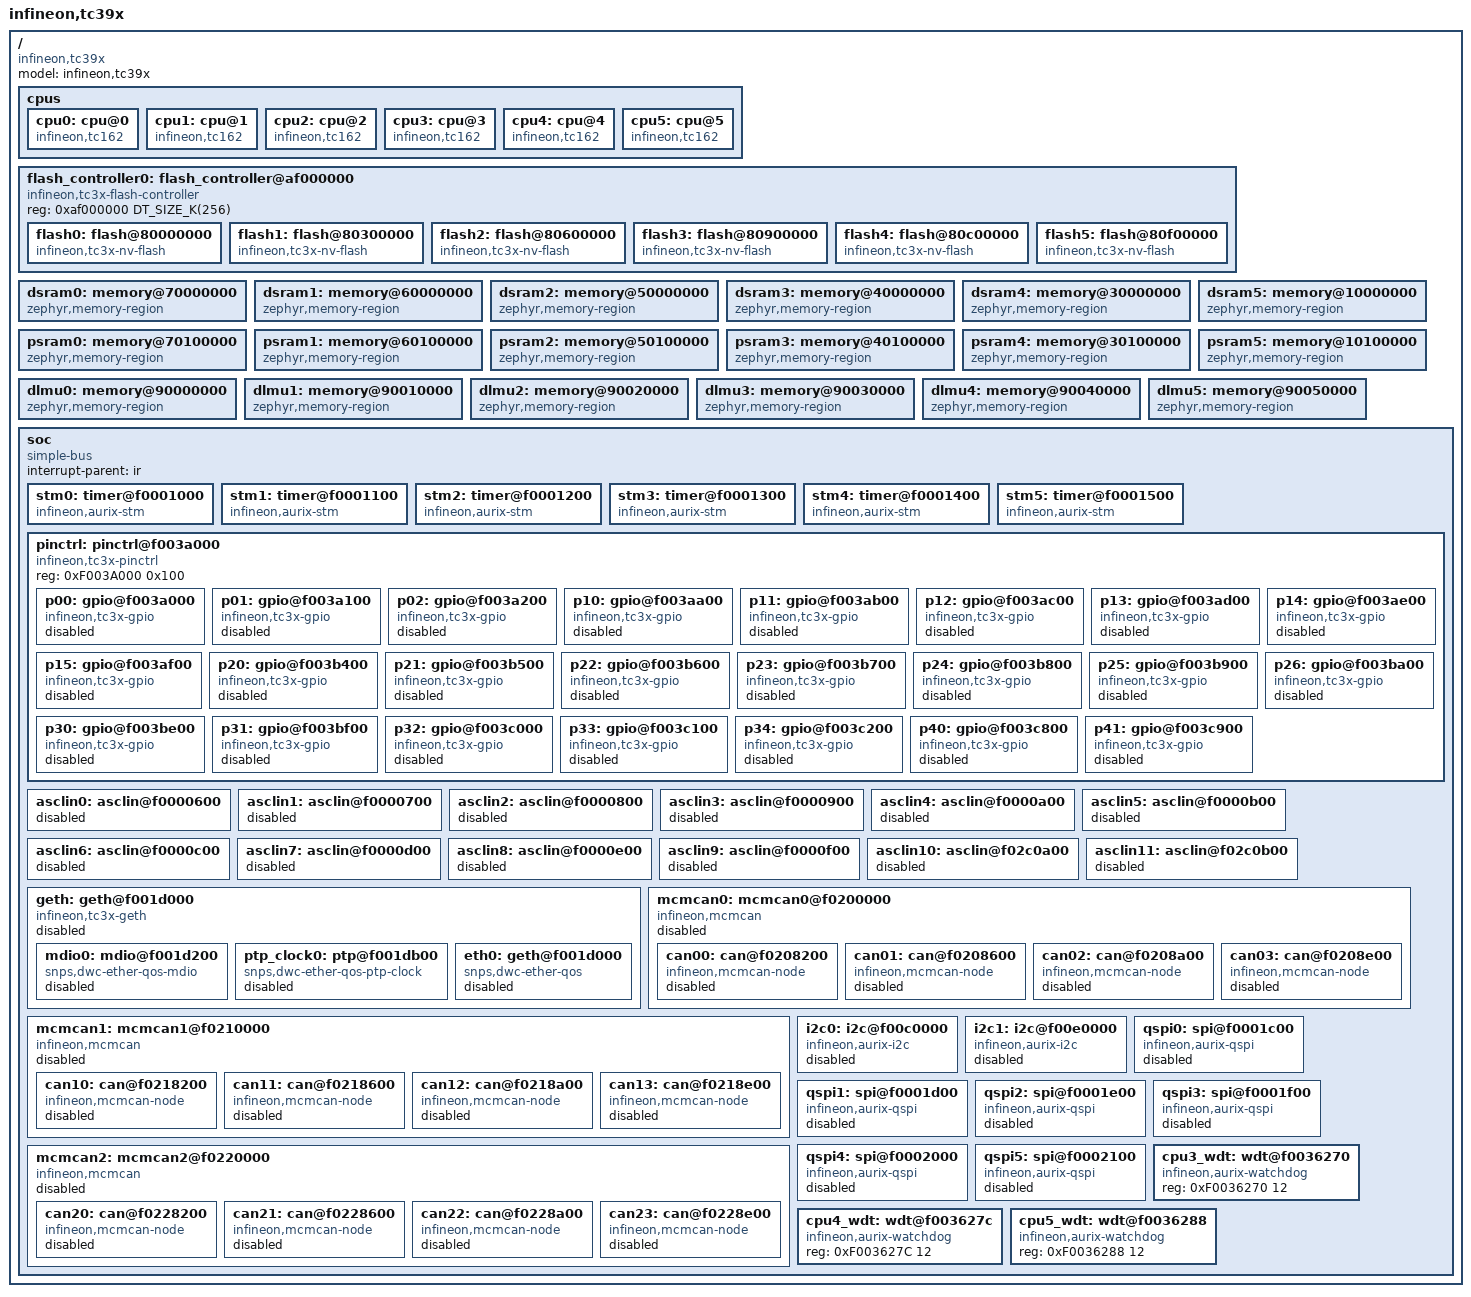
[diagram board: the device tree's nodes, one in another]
/*
 * Copyright (c) 2024 Infineon Technologies AG
 *
 * SPDX-License-Identifier: Apache-2.0
 */

#include <mem.h>
#include <freq.h>
#include <skeleton.dtsi>
#include <zephyr/dt-bindings/clock/tc3x_clock.h>
#include <zephyr/dt-bindings/gpio/gpio.h>
#include <infineon/tc3x/tc39x-irq.h>
#include <infineon/tc3x/tc3x-common.dtsi>

/ {
	model = "infineon,tc39x";
	compatible = "infineon,tc39x";

	cpus {
		#address-cells = <1>;
		#size-cells = <0>;

		cpu0: cpu@0 {
			compatible = "infineon,tc162";
			reg = <0>;
			clocks = <&fcpu0>;
		};
		cpu1: cpu@1 {
			compatible = "infineon,tc162";
			reg = <1>;
			clocks = <&fcpu1>;
		};
		cpu2: cpu@2 {
			compatible = "infineon,tc162";
			reg = <2>;
			clocks = <&fcpu2>;
		};
		cpu3: cpu@3 {
			compatible = "infineon,tc162";
			reg = <3>;
			clocks = <&fcpu3>;
		};
		cpu4: cpu@4 {
			compatible = "infineon,tc162";
			reg = <4>;
			clocks = <&fcpu4>;
		};
		cpu5: cpu@5 {
			compatible = "infineon,tc162";
			reg = <5>;
			clocks = <&fcpu5>;
		};
	};

	flash_controller0: flash_controller@af000000 {
		compatible = "infineon,tc3x-flash-controller";
		#address-cells = <1>;
		#size-cells = <1>;
		reg = <0xaf000000 DT_SIZE_K(256)>;
		flash0: flash@80000000 {
			compatible = "infineon,tc3x-nv-flash","soc-nv-flash";
			write-block-size = <256>;
			reg = <0x80000000 DT_SIZE_M(3)>;
		};
		flash1: flash@80300000 {
			compatible = "infineon,tc3x-nv-flash","soc-nv-flash";
			write-block-size = <256>;
			reg = <0x80300000 DT_SIZE_M(3)>;
		};
		flash2: flash@80600000 {
			compatible = "infineon,tc3x-nv-flash","soc-nv-flash";
			write-block-size = <256>;
			reg = <0x80600000 DT_SIZE_M(3)>;
		};
		flash3: flash@80900000 {
			compatible = "infineon,tc3x-nv-flash","soc-nv-flash";
			write-block-size = <256>;
			reg = <0x80900000 DT_SIZE_M(3)>;
		};
		flash4: flash@80c00000 {
			compatible = "infineon,tc3x-nv-flash","soc-nv-flash";
			write-block-size = <256>;
			reg = <0x80c00000 DT_SIZE_M(3)>;
		};
		flash5: flash@80f00000 {
			compatible = "infineon,tc3x-nv-flash","soc-nv-flash";
			write-block-size = <256>;
			reg = <0x80f00000 DT_SIZE_M(1)>;
		};
	};

	dsram0: memory@70000000 {
		compatible = "zephyr,memory-region","mmio-sram";
		reg = <0x70000000 DT_SIZE_K(240)>;
		zephyr,memory-region = "DSRAM0";
	};
	dsram1: memory@60000000 {
		compatible = "zephyr,memory-region","mmio-sram";
		reg = <0x60000000 DT_SIZE_K(240)>;
		zephyr,memory-region = "DSRAM1";
	};
	dsram2: memory@50000000 {
		compatible = "zephyr,memory-region","mmio-sram";
		reg = <0x50000000 DT_SIZE_K(96)>;
		zephyr,memory-region = "DSRAM2";
	};
	dsram3: memory@40000000 {
		compatible = "zephyr,memory-region","mmio-sram";
		reg = <0x40000000 DT_SIZE_K(96)>;
		zephyr,memory-region = "DSRAM3";
	};
	dsram4: memory@30000000 {
		compatible = "zephyr,memory-region","mmio-sram";
		reg = <0x30000000 DT_SIZE_K(96)>;
		zephyr,memory-region = "DSRAM4";
	};
	dsram5: memory@10000000 {
		compatible = "zephyr,memory-region","mmio-sram";
		reg = <0x10000000 DT_SIZE_K(96)>;
		zephyr,memory-region = "DSRAM5";
	};

	psram0: memory@70100000 {
		compatible = "zephyr,memory-region","mmio-sram";
		reg = <0x70100000 DT_SIZE_K(64)>;
		zephyr,memory-region = "PSRAM0";
	};
	psram1: memory@60100000 {
		compatible = "zephyr,memory-region","mmio-sram";
		reg = <0x60100000 DT_SIZE_K(64)>;
		zephyr,memory-region = "PSRAM1";
	};
	psram2: memory@50100000 {
		compatible = "zephyr,memory-region","mmio-sram";
		reg = <0x50100000 DT_SIZE_K(64)>;
		zephyr,memory-region = "PSRAM2";
	};
	psram3: memory@40100000 {
		compatible = "zephyr,memory-region","mmio-sram";
		reg = <0x40100000 DT_SIZE_K(64)>;
		zephyr,memory-region = "PSRAM3";
	};
	psram4: memory@30100000 {
		compatible = "zephyr,memory-region","mmio-sram";
		reg = <0x30100000 DT_SIZE_K(64)>;
		zephyr,memory-region = "PSRAM4";
	};
	psram5: memory@10100000 {
		compatible = "zephyr,memory-region","mmio-sram";
		reg = <0x10100000 DT_SIZE_K(64)>;
		zephyr,memory-region = "PSRAM5";
	};

	dlmu0: memory@90000000 {
		compatible = "zephyr,memory-region","mmio-sram";
		reg = <0x90000000 DT_SIZE_K(64)>;
		zephyr,memory-region = "DLMU0";
	};

	dlmu1: memory@90010000 {
		compatible = "zephyr,memory-region","mmio-sram";
		reg = <0x90010000 DT_SIZE_K(64)>;
		zephyr,memory-region = "DLMU1";
	};

	dlmu2: memory@90020000 {
		compatible = "zephyr,memory-region","mmio-sram";
		reg = <0x90020000 DT_SIZE_K(64)>;
		zephyr,memory-region = "DLMU2";
	};

	dlmu3: memory@90030000 {
		compatible = "zephyr,memory-region","mmio-sram";
		reg = <0x90030000 DT_SIZE_K(64)>;
		zephyr,memory-region = "DLMU3";
	};

	dlmu4: memory@90040000 {
		compatible = "zephyr,memory-region","mmio-sram";
		reg = <0x90040000 DT_SIZE_K(64)>;
		zephyr,memory-region = "DLMU4";
	};

	dlmu5: memory@90050000 {
		compatible = "zephyr,memory-region","mmio-sram";
		reg = <0x90050000 DT_SIZE_K(64)>;
		zephyr,memory-region = "DLMU5";
	};

	soc {
		#address-cells = <1>;
		#size-cells = <1>;
		interrupt-parent = <&ir>;
		compatible = "simple-bus";
		ranges;

		stm0: timer@f0001000 {
			compatible = "infineon,aurix-stm";
			reg = <0xF0001000 256>;
			clocks = <&fstm>;
			interrupts = <IRQ_STM0_SR0 1>;
		};
		stm1: timer@f0001100 {
			compatible = "infineon,aurix-stm";
			reg = <0xF0001100 256>;
			clocks = <&fstm>;
			interrupts = <IRQ_STM1_SR0 1>;
		};
		stm2: timer@f0001200 {
			compatible = "infineon,aurix-stm";
			reg = <0xF0001200 256>;
			clocks = <&fstm>;
			interrupts = <IRQ_STM2_SR0 1>;
		};
		stm3: timer@f0001300 {
			compatible = "infineon,aurix-stm";
			reg = <0xF0001300 256>;
			clocks = <&fstm>;
			interrupts = <IRQ_STM3_SR0 1>;
		};
		stm4: timer@f0001400 {
			compatible = "infineon,aurix-stm";
			reg = <0xF0001400 256>;
			clocks = <&fstm>;
			interrupts = <IRQ_STM4_SR0 1>;
		};
		stm5: timer@f0001500 {
			compatible = "infineon,aurix-stm";
			reg = <0xF0001500 256>;
			clocks = <&fstm>;
			interrupts = <IRQ_STM5_SR0 1>;
		};

		pinctrl: pinctrl@f003a000 {
			compatible = "infineon,tc3x-pinctrl";
			reg = <0xF003A000 0x100>;
			#address-cells = <1>;
			#size-cells = <1>;

			p00: gpio@f003a000 {
				compatible = "infineon,tc3x-gpio";
				reg = <0xF003A000 0x100>;
				gpio-controller;
				#gpio-cells = <2>;
				status = "disabled";
			};
			p01: gpio@f003a100 {
				compatible = "infineon,tc3x-gpio";
				reg = <0xF003A100 0x100>;
				gpio-controller;
				#gpio-cells = <2>;
				status = "disabled";
			};
			p02: gpio@f003a200 {
				compatible = "infineon,tc3x-gpio";
				reg = <0xF003A200 0x100>;
				gpio-controller;
				#gpio-cells = <2>;
				status = "disabled";
			};
			p10: gpio@f003aa00 {
				compatible = "infineon,tc3x-gpio";
				reg = <0xF003AA00 0x100>;
				gpio-controller;
				#gpio-cells = <2>;
				status = "disabled";
			};
			p11: gpio@f003ab00 {
				compatible = "infineon,tc3x-gpio";
				reg = <0xF003AB00 0x100>;
				gpio-controller;
				#gpio-cells = <2>;
				status = "disabled";
			};
			p12: gpio@f003ac00 {
				compatible = "infineon,tc3x-gpio";
				reg = <0xF003AC00 0x100>;
				gpio-controller;
				#gpio-cells = <2>;
				status = "disabled";
			};
			p13: gpio@f003ad00 {
				compatible = "infineon,tc3x-gpio";
				reg = <0xF003AD00 0x100>;
				gpio-controller;
				#gpio-cells = <2>;
				status = "disabled";
			};
			p14: gpio@f003ae00 {
				compatible = "infineon,tc3x-gpio";
				reg = <0xF003AE00 0x100>;
				gpio-controller;
				#gpio-cells = <2>;
				status = "disabled";
			};
			p15: gpio@f003af00 {
				compatible = "infineon,tc3x-gpio";
				reg = <0xF003AF00 0x100>;
				gpio-controller;
				#gpio-cells = <2>;
				status = "disabled";
			};
			p20: gpio@f003b400 {
				compatible = "infineon,tc3x-gpio";
				reg = <0xF003B400 0x100>;
				gpio-controller;
				#gpio-cells = <2>;
				status = "disabled";
			};
			p21: gpio@f003b500 {
				compatible = "infineon,tc3x-gpio";
				reg = <0xF003B500 0x100>;
				gpio-controller;
				#gpio-cells = <2>;
				status = "disabled";
			};
			p22: gpio@f003b600 {
				compatible = "infineon,tc3x-gpio";
				reg = <0xF003B600 0x100>;
				gpio-controller;
				#gpio-cells = <2>;
				status = "disabled";
			};
			p23: gpio@f003b700 {
				compatible = "infineon,tc3x-gpio";
				reg = <0xF003B700 0x100>;
				gpio-controller;
				#gpio-cells = <2>;
				status = "disabled";
			};
			p24: gpio@f003b800 {
				compatible = "infineon,tc3x-gpio";
				reg = <0xF003B800 0x100>;
				gpio-controller;
				#gpio-cells = <2>;
				status = "disabled";
			};
			p25: gpio@f003b900 {
				compatible = "infineon,tc3x-gpio";
				reg = <0xF003B900 0x100>;
				gpio-controller;
				#gpio-cells = <2>;
				status = "disabled";
			};
			p26: gpio@f003ba00 {
				compatible = "infineon,tc3x-gpio";
				reg = <0xF003BA00 0x100>;
				gpio-controller;
				#gpio-cells = <2>;
				status = "disabled";
			};
			p30: gpio@f003be00 {
				compatible = "infineon,tc3x-gpio";
				reg = <0xF003BE00 0x100>;
				gpio-controller;
				#gpio-cells = <2>;
				status = "disabled";
			};
			p31: gpio@f003bf00 {
				compatible = "infineon,tc3x-gpio";
				reg = <0xF003BF00 0x100>;
				gpio-controller;
				#gpio-cells = <2>;
				status = "disabled";
			};
			p32: gpio@f003c000 {
				compatible = "infineon,tc3x-gpio";
				reg = <0xF003C000 0x100>;
				gpio-controller;
				#gpio-cells = <2>;
				status = "disabled";
			};
			p33: gpio@f003c100 {
				compatible = "infineon,tc3x-gpio";
				reg = <0xF003C100 0x100>;
				gpio-controller;
				#gpio-cells = <2>;
				status = "disabled";
			};
			p34: gpio@f003c200 {
				compatible = "infineon,tc3x-gpio";
				reg = <0xF003C200 0x100>;
				gpio-controller;
				#gpio-cells = <2>;
				status = "disabled";
			};
			p40: gpio@f003c800 {
				compatible = "infineon,tc3x-gpio";
				reg = <0xF003C800 0x100>;
				gpio-controller;
				#gpio-cells = <2>;
				status = "disabled";
			};
			p41: gpio@f003c900 {
				compatible = "infineon,tc3x-gpio";
				reg = <0xF003C900 0x100>;
				gpio-controller;
				#gpio-cells = <2>;
				status = "disabled";
			};
		};

		asclin0: asclin@f0000600 {
			reg = <0xF0000600 256>;
			interrupts = <IRQ_ASCLIN0_TX 2>,
			             <IRQ_ASCLIN0_RX 3>,
			             <IRQ_ASCLIN0_ERR 4>;
			interrupt-names = "tx", "rx", "err";
			clocks = <&ccu CLOCK_FASCLINF>, <&ccu CLOCK_FASCLINS>;
			clock-names = "fasclinf", "fasclins";
			status = "disabled";
		};
		asclin1: asclin@f0000700 {
			reg = <0xF0000700 256>;
			interrupts = <IRQ_ASCLIN1_TX 2>,
			             <IRQ_ASCLIN1_RX 3>,
			             <IRQ_ASCLIN1_ERR 4>;
			interrupt-names = "tx", "rx", "err";
			clocks = <&ccu CLOCK_FASCLINF>, <&ccu CLOCK_FASCLINS>;
			clock-names = "fasclinf", "fasclins";
			status = "disabled";
		};
		asclin2: asclin@f0000800 {
			reg = <0xF0000800 256>;
			interrupts = <IRQ_ASCLIN2_TX 2>,
			             <IRQ_ASCLIN2_RX 3>,
			             <IRQ_ASCLIN2_ERR 4>;
			interrupt-names = "tx", "rx", "err";
			clocks = <&ccu CLOCK_FASCLINF>, <&ccu CLOCK_FASCLINS>;
			clock-names = "fasclinf", "fasclins";
			status = "disabled";
		};
		asclin3: asclin@f0000900 {
			reg = <0xF0000900 256>;
			interrupts = <IRQ_ASCLIN3_TX 2>,
			             <IRQ_ASCLIN3_RX 3>,
			             <IRQ_ASCLIN3_ERR 4>;
			interrupt-names = "tx", "rx", "err";
			clocks = <&ccu CLOCK_FASCLINF>, <&ccu CLOCK_FASCLINS>;
			clock-names = "fasclinf", "fasclins";
			status = "disabled";
		};
		asclin4: asclin@f0000a00 {
			reg = <0xF0000A00 256>;
			interrupts = <IRQ_ASCLIN4_TX 2>,
			             <IRQ_ASCLIN4_RX 3>,
			             <IRQ_ASCLIN4_ERR 4>;
			interrupt-names = "tx", "rx", "err";
			clocks = <&ccu CLOCK_FASCLINF>, <&ccu CLOCK_FASCLINS>;
			clock-names = "fasclinf", "fasclins";
			status = "disabled";
		};
		asclin5: asclin@f0000b00 {
			reg = <0xF0000B00 256>;
			interrupts = <IRQ_ASCLIN5_TX 2>,
			             <IRQ_ASCLIN5_RX 3>,
			             <IRQ_ASCLIN5_ERR 4>;
			interrupt-names = "tx", "rx", "err";
			clocks = <&ccu CLOCK_FASCLINF>, <&ccu CLOCK_FASCLINS>;
			clock-names = "fasclinf", "fasclins";
			status = "disabled";
		};
		asclin6: asclin@f0000c00 {
			reg = <0xF0000C00 256>;
			interrupts = <IRQ_ASCLIN6_TX 2>,
			             <IRQ_ASCLIN6_RX 3>,
			             <IRQ_ASCLIN6_ERR 4>;
			interrupt-names = "tx", "rx", "err";
			clocks = <&ccu CLOCK_FASCLINF>, <&ccu CLOCK_FASCLINS>;
			clock-names = "fasclinf", "fasclins";
			status = "disabled";
		};
		asclin7: asclin@f0000d00 {
			reg = <0xF0000D00 256>;
			interrupts = <IRQ_ASCLIN7_TX 2>,
			             <IRQ_ASCLIN7_RX 3>,
			             <IRQ_ASCLIN7_ERR 4>;
			interrupt-names = "tx", "rx", "err";
			clocks = <&ccu CLOCK_FASCLINF>, <&ccu CLOCK_FASCLINS>;
			clock-names = "fasclinf", "fasclins";
			status = "disabled";
		};
		asclin8: asclin@f0000e00 {
			reg = <0xF0000E00 256>;
			interrupts = <IRQ_ASCLIN8_TX 2>,
			             <IRQ_ASCLIN8_RX 3>,
			             <IRQ_ASCLIN8_ERR 4>;
			interrupt-names = "tx", "rx", "err";
			clocks = <&ccu CLOCK_FASCLINF>, <&ccu CLOCK_FASCLINS>;
			clock-names = "fasclinf", "fasclins";
			status = "disabled";
		};
		asclin9: asclin@f0000f00 {
			reg = <0xF0000F00 256>;
			interrupts = <IRQ_ASCLIN9_TX 2>, <IRQ_ASCLIN9_RX 3>, <IRQ_ASCLIN9_ERR 4>;
			interrupt-names = "tx", "rx", "err";
			clocks = <&ccu CLOCK_FASCLINF>, <&ccu CLOCK_FASCLINS>;
			clock-names = "fasclinf", "fasclins";
			status = "disabled";
		};
		asclin10: asclin@f02c0a00 {
			reg = <0xF02C0A00 0x100>;
			interrupts = <IRQ_ASCLIN10_TX 2>,
			             <IRQ_ASCLIN10_RX 3>,
			             <IRQ_ASCLIN10_ERR 4>;
			interrupt-names = "tx", "rx", "err";
			clocks = <&ccu CLOCK_FASCLINF>, <&ccu CLOCK_FASCLINS>;
			clock-names = "fasclinf", "fasclins";
			status = "disabled";
		};
		asclin11: asclin@f02c0b00 {
			reg = <0xF02C0B00 0x100>;
			interrupts = <IRQ_ASCLIN11_TX 2>,
			             <IRQ_ASCLIN11_RX 3>,
			             <IRQ_ASCLIN11_ERR 4>;
			interrupt-names = "tx", "rx", "err";
			clocks = <&ccu CLOCK_FASCLINF>, <&ccu CLOCK_FASCLINS>;
			clock-names = "fasclinf", "fasclins";
			status = "disabled";
		};

		geth: geth@f001d000 {
			reg = <0xF001D000 0x2100>;
			compatible = "infineon,tc3x-geth";
			#address-cells = <1>;
			#size-cells = <1>;
			clocks = <&ccu CLOCK_FSPB>, <&ccu CLOCK_FGETH>, <&ccu CLOCK_FGETH>;
			clock-names = "csr", "app", "ptp";
			status = "disabled";

			mdio0: mdio@f001d200 {
				compatible = "snps,dwc-ether-qos-mdio";
				reg = <0xF001D200 0x8>;
				#address-cells = <1>;
				#size-cells = <0>;
				clocks = <&ccu CLOCK_FSPB>;
				clock-names = "csr";
				status = "disabled";
			};

			ptp_clock0: ptp@f001db00 {
				compatible = "snps,dwc-ether-qos-ptp-clock";
				reg = <0xF001DB00 0x20>;
				clocks = <&ccu CLOCK_FGETH>;
				status = "disabled";
			};

			eth0: geth@f001d000 {
				compatible = "snps,dwc-ether-qos";
				reg = <0xF001D000 0x2000>;
				interrupts = <IRQ_GETH0_SR0 10>,
				             <IRQ_GETH0_SR2 12>,
				             <IRQ_GETH0_SR3 13>,
				             <IRQ_GETH0_SR4 14>,
				             <IRQ_GETH0_SR5 15>,
				             <IRQ_GETH0_SR6 16>,
				             <IRQ_GETH0_SR7 17>,
				             <IRQ_GETH0_SR8 18>,
				             <IRQ_GETH0_SR9 19>;
				interrupt-names = "common",
				                  "tx_ch0",
				                  "tx_ch1",
				                  "tx_ch2",
				                  "tx_ch3",
				                  "rx_ch0",
				                  "rx_ch1",
				                  "rx_ch2",
				                  "rx_ch3";
				ptp-clock = <&ptp_clock0>;
				snps,address-aligned-burst;
				snps,fixed-burst-length;
				snps,burst-length = <8>;
				status = "disabled";
			};
		};

		mcmcan0: mcmcan0@f0200000 {
			compatible = "infineon,mcmcan";
			#address-cells = <1>;
			#size-cells = <1>;
			reg = <0xF0200000 0x9000>;
			clocks = <&ccu CLOCK_FMCAN>, <&ccu CLOCK_FMCANH>;
			status = "disabled";

			can00: can@f0208200 {
				compatible = "infineon,mcmcan-node";
				reg = <0xF0208200 0x200>, <0xF0200000 0x8000>;
				reg-names = "m_can", "message_ram";
				interrupts = <IRQ_CAN0_INT0 10>, <IRQ_CAN0_INT1 11>;
				interrupt-names = "line0", "line1";
				bosch,mram-cfg = <0x0 32 32 32 32 0 16 16>;
				sample-point = <875>;
				sample-point-data = <875>;
				bitrate = <500000>;
				bitrate-data = <2000000>;
				status = "disabled";
			};
			can01: can@f0208600 {
				compatible = "infineon,mcmcan-node";
				reg = <0xF0208600 0x200>, <0xF0200000 0x8000>;
				reg-names = "m_can", "message_ram";
				interrupts = <IRQ_CAN0_INT2 10>, <IRQ_CAN0_INT3 11>;
				interrupt-names = "line0", "line1";
				bosch,mram-cfg = <0x0 32 32 32 32 0 16 16>;
				sample-point = <875>;
				sample-point-data = <875>;
				bitrate = <500000>;
				bitrate-data = <2000000>;
				status = "disabled";
			};
			can02: can@f0208a00 {
				compatible = "infineon,mcmcan-node";
				reg = <0xF0208A00 0x200>, <0xF0200000 0x8000>;
				reg-names = "m_can", "message_ram";
				interrupts = <IRQ_CAN0_INT4 10>, <IRQ_CAN0_INT5 11>;
				interrupt-names = "line0", "line1";
				bosch,mram-cfg = <0x0 32 32 32 32 0 16 16>;
				sample-point = <875>;
				sample-point-data = <875>;
				bitrate = <500000>;
				bitrate-data = <2000000>;
				status = "disabled";
			};
			can03: can@f0208e00 {
				compatible = "infineon,mcmcan-node";
				reg = <0xF0208E00 0x200>, <0xF0200000 0x8000>;
				reg-names = "m_can", "message_ram";
				interrupts = <IRQ_CAN0_INT6 10>, <IRQ_CAN0_INT7 11>;
				interrupt-names = "line0", "line1";
				bosch,mram-cfg = <0x0 32 32 32 32 0 16 16>;
				sample-point = <875>;
				sample-point-data = <875>;
				bitrate = <500000>;
				bitrate-data = <2000000>;
				status = "disabled";
			};
		};

		mcmcan1: mcmcan1@f0210000 {
			compatible = "infineon,mcmcan";
			#address-cells = <1>;
			#size-cells = <1>;
			reg = <0xF0210000 0x9000>;
			clocks = <&ccu CLOCK_FMCAN>, <&ccu CLOCK_FMCANH>;
			status = "disabled";

			can10: can@f0218200 {
				compatible = "infineon,mcmcan-node";
				reg = <0xF0218200 0x200>, <0xF0210000 0x8000>;
				reg-names = "m_can", "message_ram";
				interrupts = <IRQ_CAN1_INT0 10>, <IRQ_CAN1_INT1 11>;
				interrupt-names = "line0", "line1";
				bosch,mram-cfg = <0x0 32 32 32 32 0 16 16>;
				sample-point = <875>;
				sample-point-data = <875>;
				bitrate = <500000>;
				bitrate-data = <2000000>;
				status = "disabled";
			};
			can11: can@f0218600 {
				compatible = "infineon,mcmcan-node";
				reg = <0xF0218600 0x200>, <0xF0210000 0x8000>;
				reg-names = "m_can", "message_ram";
				interrupts = <IRQ_CAN1_INT2 10>, <IRQ_CAN1_INT3 11>;
				interrupt-names = "line0", "line1";
				bosch,mram-cfg = <0x0 32 32 32 32 0 16 16>;
				sample-point = <875>;
				sample-point-data = <875>;
				bitrate = <500000>;
				bitrate-data = <2000000>;
				status = "disabled";
			};
			can12: can@f0218a00 {
				compatible = "infineon,mcmcan-node";
				reg = <0xF0218A00 0x200>, <0xF0210000 0x8000>;
				reg-names = "m_can", "message_ram";
				interrupts = <IRQ_CAN1_INT4 10>, <IRQ_CAN1_INT5 11>;
				interrupt-names = "line0", "line1";
				bosch,mram-cfg = <0x0 32 32 32 32 0 16 16>;
				sample-point = <875>;
				sample-point-data = <875>;
				bitrate = <500000>;
				bitrate-data = <2000000>;
				status = "disabled";
			};
			can13: can@f0218e00 {
				compatible = "infineon,mcmcan-node";
				reg = <0xF0218E00 0x200>, <0xF0210000 0x8000>;
				reg-names = "m_can", "message_ram";
				interrupts = <IRQ_CAN1_INT6 10>, <IRQ_CAN1_INT7 11>;
				interrupt-names = "line0", "line1";
				bosch,mram-cfg = <0x0 32 32 32 32 0 16 16>;
				sample-point = <875>;
				sample-point-data = <875>;
				bitrate = <500000>;
				bitrate-data = <2000000>;
				status = "disabled";
			};
		};
		mcmcan2: mcmcan2@f0220000 {
			compatible = "infineon,mcmcan";
			#address-cells = <1>;
			#size-cells = <1>;
			reg = <0xF0220000 0x9000>;
			clocks = <&ccu CLOCK_FMCAN>, <&ccu CLOCK_FMCANH>;
			status = "disabled";

			can20: can@f0228200 {
				compatible = "infineon,mcmcan-node";
				reg = <0xF0228200 0x200>, <0xF0220000 0x8000>;
				reg-names = "m_can", "message_ram";
				interrupts = <IRQ_CAN2_INT0 10>, <IRQ_CAN2_INT1 11>;
				interrupt-names = "line0", "line1";
				bosch,mram-cfg = <0x0 32 32 32 32 0 16 16>;
				sample-point = <875>;
				sample-point-data = <875>;
				bitrate = <500000>;
				bitrate-data = <2000000>;
				status = "disabled";
			};
			can21: can@f0228600 {
				compatible = "infineon,mcmcan-node";
				reg = <0xF0228600 0x200>, <0xF0220000 0x8000>;
				reg-names = "m_can", "message_ram";
				interrupts = <IRQ_CAN2_INT2 10>, <IRQ_CAN2_INT3 11>;
				interrupt-names = "line0", "line1";
				bosch,mram-cfg = <0x0 32 32 32 32 0 16 16>;
				sample-point = <875>;
				sample-point-data = <875>;
				bitrate = <500000>;
				bitrate-data = <2000000>;
				status = "disabled";
			};
			can22: can@f0228a00 {
				compatible = "infineon,mcmcan-node";
				reg = <0xF0228A00 0x200>, <0xF0220000 0x8000>;
				reg-names = "m_can", "message_ram";
				interrupts = <IRQ_CAN2_INT4 10>, <IRQ_CAN2_INT5 11>;
				interrupt-names = "line0", "line1";
				bosch,mram-cfg = <0x0 32 32 32 32 0 16 16>;
				sample-point = <875>;
				sample-point-data = <875>;
				bitrate = <500000>;
				bitrate-data = <2000000>;
				status = "disabled";
			};
			can23: can@f0228e00 {
				compatible = "infineon,mcmcan-node";
				reg = <0xF0228E00 0x200>, <0xF0220000 0x8000>;
				reg-names = "m_can", "message_ram";
				interrupts = <IRQ_CAN2_INT6 10>, <IRQ_CAN2_INT7 11>;
				interrupt-names = "line0", "line1";
				bosch,mram-cfg = <0x0 32 32 32 32 0 16 16>;
				sample-point = <875>;
				sample-point-data = <875>;
				bitrate = <500000>;
				bitrate-data = <2000000>;
				status = "disabled";
			};
		};

		i2c0: i2c@f00c0000 {
			compatible = "infineon,aurix-i2c";
			reg = <0xF00C0000 0x20000>;
			#address-cells = <1>;
			#size-cells = <0>;
			clocks = <&ccu CLOCK_FI2C>;
			interrupts = <IRQ_I2C0_DTR 5>, <IRQ_I2C0_ERR 6>, <IRQ_I2C0_P 5>;
			interrupt-names = "data_transfer", "error", "protocol";
			status = "disabled";
		};
		i2c1: i2c@f00e0000 {
			compatible = "infineon,aurix-i2c";
			reg = <0xF00E0000 0x20000>;
			#address-cells = <1>;
			#size-cells = <0>;
			clocks = <&ccu CLOCK_FI2C>;
			interrupts = <IRQ_I2C1_DTR 5>, <IRQ_I2C1_ERR 6>, <IRQ_I2C1_P 5>;
			interrupt-names = "data_transfer", "error", "protocol";
			status = "disabled";
		};

		qspi0: spi@f0001c00 {
			compatible = "infineon,aurix-qspi";
			reg = <0xF0001C00 0x100>;
			#address-cells = <1>;
			#size-cells = <0>;
			interrupts = <IRQ_QSPI0_TX 0x2>,
			             <IRQ_QSPI0_RX 0x3>,
			             <IRQ_QSPI0_ERR 0x3>;
			interrupt-names = "tx", "rx", "err";
			clocks = <&ccu CLOCK_FQSPI>;
			status = "disabled";
		};
		qspi1: spi@f0001d00 {
			compatible = "infineon,aurix-qspi";
			reg = <0xF0001d00 0x100>;
			#address-cells = <1>;
			#size-cells = <0>;
			interrupts = <IRQ_QSPI1_TX 0x2>,
			             <IRQ_QSPI1_RX 0x3>,
			             <IRQ_QSPI1_ERR 0x3>;
			interrupt-names = "tx", "rx", "err";
			clocks = <&ccu CLOCK_FQSPI>;
			status = "disabled";
		};
		qspi2: spi@f0001e00 {
			compatible = "infineon,aurix-qspi";
			reg = <0xF0001E00 0x100>;
			#address-cells = <1>;
			#size-cells = <0>;
			interrupts = <IRQ_QSPI2_TX 0x2>,
			             <IRQ_QSPI2_RX 0x3>,
			             <IRQ_QSPI2_ERR 0x3>;
			interrupt-names = "tx", "rx", "err";
			clocks = <&ccu CLOCK_FQSPI>;
			status = "disabled";
		};
		qspi3: spi@f0001f00 {
			compatible = "infineon,aurix-qspi";
			reg = <0xF0001f00 0x100>;
			#address-cells = <1>;
			#size-cells = <0>;
			interrupts = <IRQ_QSPI3_TX 0x2>,
			             <IRQ_QSPI3_RX 0x3>,
			             <IRQ_QSPI3_ERR 0x3>;
			interrupt-names = "tx", "rx", "err";
			clocks = <&ccu CLOCK_FQSPI>;
			status = "disabled";
		};
		qspi4: spi@f0002000 {
			compatible = "infineon,aurix-qspi";
			reg = <0xF0002000 0x100>;
			#address-cells = <1>;
			#size-cells = <0>;
			interrupts = <IRQ_QSPI4_TX 0x2>,
			             <IRQ_QSPI4_RX 0x3>,
			             <IRQ_QSPI4_ERR 0x3>;
			interrupt-names = "tx", "rx", "err";
			clocks = <&ccu CLOCK_FQSPI>;
			status = "disabled";
		};
		qspi5: spi@f0002100 {
			compatible = "infineon,aurix-qspi";
			reg = <0xF0002100 0x100>;
			#address-cells = <1>;
			#size-cells = <0>;
			interrupts = <IRQ_QSPI5_TX 0x2>,
			             <IRQ_QSPI5_RX 0x3>,
			             <IRQ_QSPI5_ERR 0x3>;
			interrupt-names = "tx", "rx", "err";
			clocks = <&ccu CLOCK_FQSPI>;
			status = "disabled";
		};

		cpu3_wdt: wdt@f0036270 {
			compatible = "infineon,aurix-watchdog";
			reg = <0xF0036270 12>;
			status = "okay";
		};

		cpu4_wdt: wdt@f003627c {
			compatible = "infineon,aurix-watchdog";
			reg = <0xF003627C 12>;
			status = "okay";
		};

		cpu5_wdt: wdt@f0036288 {
			compatible = "infineon,aurix-watchdog";
			reg = <0xF0036288 12>;
			status = "okay";
		};
	};
};
